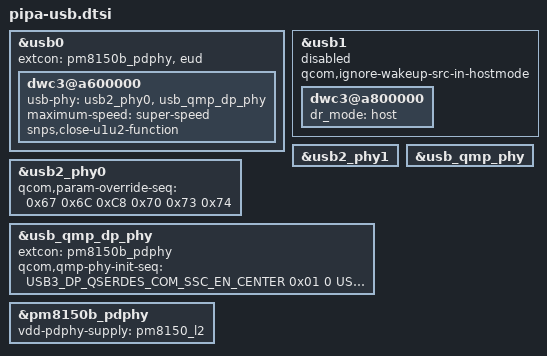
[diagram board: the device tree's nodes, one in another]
/* Pipa USB-C and USB3 configuration from pipa-dts/qcom/pipa-sm8250.dtsi. */
#include <dt-bindings/phy/qcom,kona-qmp-usb3.h>

&usb0 {
	extcon = <&pm8150b_pdphy>, <&eud>;
	dwc3@a600000 {
		usb-phy = <&usb2_phy0>, <&usb_qmp_dp_phy>;
		maximum-speed = "super-speed";
		snps,close-u1u2-function;
	};
};

&usb1 {
	status = "disable";
	qcom,ignore-wakeup-src-in-hostmode;

	dwc3@a800000 {
		dr_mode = "host";
	};
};

&usb2_phy1 {
        status = "ok";
};

&usb_qmp_phy {
        status = "ok";
};

/* The 5.4 HS PHY driver does not consume the country-specific global override. */
&usb2_phy0 {
	qcom,param-override-seq =
		<0x67 0x6C
		 0xC8 0x70
		 0x73 0x74>;
};

&usb_qmp_dp_phy {
	extcon = <&pm8150b_pdphy>;
		status = "ok";
		qcom,qmp-phy-init-seq =
			/* <reg_offset, value, delay> */
			<USB3_DP_QSERDES_COM_SSC_EN_CENTER 0x01 0
			USB3_DP_QSERDES_COM_SSC_PER1 0x31 0
			USB3_DP_QSERDES_COM_SSC_PER2 0x01 0
			USB3_DP_QSERDES_COM_SSC_STEP_SIZE1_MODE0 0xDE 0
			USB3_DP_QSERDES_COM_SSC_STEP_SIZE2_MODE0 0x07 0
			USB3_DP_QSERDES_COM_SSC_STEP_SIZE1_MODE1 0xDE 0
			USB3_DP_QSERDES_COM_SSC_STEP_SIZE2_MODE1 0x07 0
			USB3_DP_QSERDES_COM_SYSCLK_BUF_ENABLE 0x0A 0
			USB3_DP_QSERDES_COM_CMN_IPTRIM 0x20 0
			USB3_DP_QSERDES_COM_CP_CTRL_MODE0 0x06 0
			USB3_DP_QSERDES_COM_CP_CTRL_MODE1 0x06 0
			USB3_DP_QSERDES_COM_PLL_RCTRL_MODE0 0x16 0
			USB3_DP_QSERDES_COM_PLL_RCTRL_MODE1 0x16 0
			USB3_DP_QSERDES_COM_PLL_CCTRL_MODE0 0x36 0
			USB3_DP_QSERDES_COM_PLL_CCTRL_MODE1 0x36 0
			USB3_DP_QSERDES_COM_SYSCLK_EN_SEL 0x1A 0
			USB3_DP_QSERDES_COM_LOCK_CMP_EN 0x04 0
			USB3_DP_QSERDES_COM_LOCK_CMP1_MODE0 0x14 0
			USB3_DP_QSERDES_COM_LOCK_CMP2_MODE0 0x34 0
			USB3_DP_QSERDES_COM_LOCK_CMP1_MODE1 0x34 0
			USB3_DP_QSERDES_COM_LOCK_CMP2_MODE1 0x82 0
			USB3_DP_QSERDES_COM_DEC_START_MODE0 0x82 0
			USB3_DP_QSERDES_COM_DEC_START_MODE1 0x82 0
			USB3_DP_QSERDES_COM_DIV_FRAC_START1_MODE0 0xAB 0
			USB3_DP_QSERDES_COM_DIV_FRAC_START2_MODE0 0xEA 0
			USB3_DP_QSERDES_COM_DIV_FRAC_START3_MODE0 0x02 0
			USB3_DP_QSERDES_COM_DIV_FRAC_START1_MODE1 0xAB 0
			USB3_DP_QSERDES_COM_DIV_FRAC_START2_MODE1 0xEA 0
			USB3_DP_QSERDES_COM_DIV_FRAC_START3_MODE1 0x02 0
			USB3_DP_QSERDES_COM_VCO_TUNE_MAP 0x02 0
			USB3_DP_QSERDES_COM_VCO_TUNE1_MODE0 0x24 0
			USB3_DP_QSERDES_COM_VCO_TUNE1_MODE1 0x24 0
			USB3_DP_QSERDES_COM_VCO_TUNE2_MODE1 0x02 0
			USB3_DP_QSERDES_COM_HSCLK_SEL 0x01 0
			USB3_DP_QSERDES_COM_CORECLK_DIV_MODE1 0x08 0
			USB3_DP_QSERDES_COM_BIN_VCOCAL_CMP_CODE1_MODE0 0xCA 0
			USB3_DP_QSERDES_COM_BIN_VCOCAL_CMP_CODE2_MODE0 0x1E 0
			USB3_DP_QSERDES_COM_BIN_VCOCAL_CMP_CODE1_MODE1 0xCA 0
			USB3_DP_QSERDES_COM_BIN_VCOCAL_CMP_CODE2_MODE1 0x1E 0
			USB3_DP_QSERDES_COM_BIN_VCOCAL_HSCLK_SEL 0x11 0
			USB3_DP_QSERDES_TXA_RES_CODE_LANE_TX 0x60 0
			USB3_DP_QSERDES_TXA_RES_CODE_LANE_RX 0x60 0
			USB3_DP_QSERDES_TXA_RES_CODE_LANE_OFFSET_TX 0x11 0
			USB3_DP_QSERDES_TXA_RES_CODE_LANE_OFFSET_RX 0x02 0
			USB3_DP_QSERDES_TXA_LANE_MODE_1 0xD5 0
			USB3_DP_QSERDES_TXA_LANE_MODE_2 0x00 0
			USB3_DP_QSERDES_TXA_RCV_DETECT_LVL_2 0x12 0
			USB3_DP_QSERDES_TXA_PI_QEC_CTRL 0x40 0
			USB3_DP_QSERDES_RXA_UCDR_FO_GAIN 0x09 0
			USB3_DP_QSERDES_RXA_UCDR_SO_GAIN 0x05 0
			USB3_DP_QSERDES_RXA_UCDR_FASTLOCK_FO_GAIN 0x2F 0
			USB3_DP_QSERDES_RXA_UCDR_SO_SATURATION_AND_ENABLE 0x7F 0
			USB3_DP_QSERDES_RXA_UCDR_FASTLOCK_COUNT_LOW 0xFF 0
			USB3_DP_QSERDES_RXA_UCDR_FASTLOCK_COUNT_HIGH 0x0F 0
			USB3_DP_QSERDES_RXA_UCDR_PI_CONTROLS 0x99 0
			USB3_DP_QSERDES_RXA_UCDR_SB2_THRESH1 0x08 0
			USB3_DP_QSERDES_RXA_UCDR_SB2_THRESH2 0x08 0
			USB3_DP_QSERDES_RXA_UCDR_SB2_GAIN1 0x00 0
			USB3_DP_QSERDES_RXA_UCDR_SB2_GAIN2 0x04 0
			USB3_DP_QSERDES_RXA_VGA_CAL_CNTRL1 0x54 0
			USB3_DP_QSERDES_RXA_VGA_CAL_CNTRL2 0x0C 0
			USB3_DP_QSERDES_RXA_RX_EQU_ADAPTOR_CNTRL2 0x0F 0
			USB3_DP_QSERDES_RXA_RX_EQU_ADAPTOR_CNTRL3 0x4A 0
			USB3_DP_QSERDES_RXA_RX_EQU_ADAPTOR_CNTRL4 0x0A 0
			USB3_DP_QSERDES_RXA_RX_IDAC_TSETTLE_LOW 0xC0 0
			USB3_DP_QSERDES_RXA_RX_IDAC_TSETTLE_HIGH 0x00 0
			USB3_DP_QSERDES_RXA_RX_EQ_OFFSET_ADAPTOR_CNTRL1 0x77 0
			USB3_DP_QSERDES_RXA_SIGDET_CNTRL 0x04 0
			USB3_DP_QSERDES_RXA_SIGDET_DEGLITCH_CNTRL 0x0E 0
			USB3_DP_QSERDES_RXA_RX_MODE_00_LOW 0xFF 0
			USB3_DP_QSERDES_RXA_RX_MODE_00_HIGH 0x7F 0
			USB3_DP_QSERDES_RXA_RX_MODE_00_HIGH2 0x7F 0
			USB3_DP_QSERDES_RXA_RX_MODE_00_HIGH3 0x7F 0
			USB3_DP_QSERDES_RXA_RX_MODE_00_HIGH4 0x97 0
			USB3_DP_QSERDES_RXA_RX_MODE_01_LOW 0xDC 0
			USB3_DP_QSERDES_RXA_RX_MODE_01_HIGH 0xDC 0
			USB3_DP_QSERDES_RXA_RX_MODE_01_HIGH2 0x5C 0
			USB3_DP_QSERDES_RXA_RX_MODE_01_HIGH3 0x7B 0
			USB3_DP_QSERDES_RXA_RX_MODE_01_HIGH4 0xB4 0
			USB3_DP_QSERDES_RXA_DFE_EN_TIMER 0x04 0
			USB3_DP_QSERDES_RXA_DFE_CTLE_POST_CAL_OFFSET 0x38 0
			USB3_DP_QSERDES_RXA_AUX_DATA_TCOARSE_TFINE 0xA0 0
			USB3_DP_QSERDES_RXA_DCC_CTRL1 0x0C 0
			USB3_DP_QSERDES_RXA_GM_CAL 0x1F 0
			USB3_DP_QSERDES_RXA_VTH_CODE 0x10 0
			USB3_DP_QSERDES_TXB_RES_CODE_LANE_TX 0x60 0
			USB3_DP_QSERDES_TXB_RES_CODE_LANE_RX 0x60 0
			USB3_DP_QSERDES_TXB_RES_CODE_LANE_OFFSET_TX 0x11 0
			USB3_DP_QSERDES_TXB_RES_CODE_LANE_OFFSET_RX 0x02 0
			USB3_DP_QSERDES_TXB_LANE_MODE_1 0xD5 0
			USB3_DP_QSERDES_TXB_LANE_MODE_2 0x00 0
			USB3_DP_QSERDES_TXB_RCV_DETECT_LVL_2 0x12 0
			USB3_DP_QSERDES_TXB_PI_QEC_CTRL 0x54 0
			USB3_DP_QSERDES_RXB_UCDR_FO_GAIN 0x09 0
			USB3_DP_QSERDES_RXB_UCDR_SO_GAIN 0x05 0
			USB3_DP_QSERDES_RXB_UCDR_FASTLOCK_FO_GAIN 0x2F 0
			USB3_DP_QSERDES_RXB_UCDR_SO_SATURATION_AND_ENABLE 0x7F 0
			USB3_DP_QSERDES_RXB_UCDR_FASTLOCK_COUNT_LOW 0xFF 0
			USB3_DP_QSERDES_RXB_UCDR_FASTLOCK_COUNT_HIGH 0x0F 0
			USB3_DP_QSERDES_RXB_UCDR_PI_CONTROLS 0x99 0
			USB3_DP_QSERDES_RXB_UCDR_SB2_THRESH1 0x08 0
			USB3_DP_QSERDES_RXB_UCDR_SB2_THRESH2 0x08 0
			USB3_DP_QSERDES_RXB_UCDR_SB2_GAIN1 0x00 0
			USB3_DP_QSERDES_RXB_UCDR_SB2_GAIN2 0x04 0
			USB3_DP_QSERDES_RXB_VGA_CAL_CNTRL1 0x54 0
			USB3_DP_QSERDES_RXB_VGA_CAL_CNTRL2 0x0C 0
			USB3_DP_QSERDES_RXB_RX_EQU_ADAPTOR_CNTRL2 0x0F 0
			USB3_DP_QSERDES_RXB_RX_EQU_ADAPTOR_CNTRL3 0x4A 0
			USB3_DP_QSERDES_RXB_RX_EQU_ADAPTOR_CNTRL4 0x0A 0
			USB3_DP_QSERDES_RXB_RX_IDAC_TSETTLE_LOW 0xC0 0
			USB3_DP_QSERDES_RXB_RX_IDAC_TSETTLE_HIGH 0x00 0
			USB3_DP_QSERDES_RXB_RX_EQ_OFFSET_ADAPTOR_CNTRL1 0x77 0
			USB3_DP_QSERDES_RXB_SIGDET_CNTRL 0x04 0
			USB3_DP_QSERDES_RXB_SIGDET_DEGLITCH_CNTRL 0x0E 0
			USB3_DP_QSERDES_RXB_RX_MODE_00_LOW 0x7F 0
			USB3_DP_QSERDES_RXB_RX_MODE_00_HIGH 0xFF 0
			USB3_DP_QSERDES_RXB_RX_MODE_00_HIGH2 0x3F 0
			USB3_DP_QSERDES_RXB_RX_MODE_00_HIGH3 0x7F 0
			USB3_DP_QSERDES_RXB_RX_MODE_00_HIGH4 0xA6 0
			USB3_DP_QSERDES_RXB_RX_MODE_01_LOW 0xDC 0
			USB3_DP_QSERDES_RXB_RX_MODE_01_HIGH 0xDC 0
			USB3_DP_QSERDES_RXB_RX_MODE_01_HIGH2 0x5C 0
			USB3_DP_QSERDES_RXB_RX_MODE_01_HIGH3 0x7B 0
			USB3_DP_QSERDES_RXB_RX_MODE_01_HIGH4 0xB4 0
			USB3_DP_QSERDES_RXB_DFE_EN_TIMER 0x04 0
			USB3_DP_QSERDES_RXB_DFE_CTLE_POST_CAL_OFFSET 0x38 0
			USB3_DP_QSERDES_RXB_AUX_DATA_TCOARSE_TFINE 0xA0 0
			USB3_DP_QSERDES_RXB_DCC_CTRL1 0x0C 0
			USB3_DP_QSERDES_RXB_GM_CAL 0x1F 0
			USB3_DP_QSERDES_RXB_VTH_CODE 0x10 0
			USB3_DP_PCS_LOCK_DETECT_CONFIG1 0xD0 0
			USB3_DP_PCS_LOCK_DETECT_CONFIG2 0x07 0
			USB3_DP_PCS_LOCK_DETECT_CONFIG3 0x20 0
			USB3_DP_PCS_LOCK_DETECT_CONFIG6 0x13 0
			USB3_DP_PCS_REFGEN_REQ_CONFIG1 0x21 0
			USB3_DP_PCS_RX_SIGDET_LVL 0xA9 0
			USB3_DP_PCS_CDR_RESET_TIME 0x0A 0
			USB3_DP_PCS_ALIGN_DETECT_CONFIG1 0x88 0
			USB3_DP_PCS_ALIGN_DETECT_CONFIG2 0x13 0
			USB3_DP_PCS_PCS_TX_RX_CONFIG 0x0C 0
			USB3_DP_PCS_EQ_CONFIG1 0x4B 0
			USB3_DP_PCS_EQ_CONFIG5 0x10 0
			USB3_DP_PCS_USB3_LFPS_DET_HIGH_COUNT_VAL 0xF8 0
			USB3_DP_PCS_USB3_RXEQTRAINING_DFE_TIME_S2 0x07 0
			USB3_DP_QSERDES_TXA_TX_DRV_LVL 0x0 0
			USB3_DP_QSERDES_TXB_TX_DRV_LVL 0x0 0
			USB3_DP_QSERDES_TXA_PRE_EMPH 0x2E 0
			USB3_DP_QSERDES_TXB_PRE_EMPH 0x2D 0
			USB3_DP_QSERDES_TXA_TX_EMP_POST1_LVL 0x01 0
			USB3_DP_QSERDES_TXB_TX_EMP_POST1_LVL 0x01 0
			USB3_DP_PCS_G12S1_TXMGN_V0 0x1F 0
			USB3_DP_PCS_G12S1_TXDEEMPH_M3P5DB 0x11 0
			USB3_DP_PCS_G3S2_TXMGN_MAIN 0x1F 0
			0xffffffff 0xffffffff 0x00>;
};

&pm8150b_pdphy {
	vdd-pdphy-supply = <&pm8150_l2>;
};
